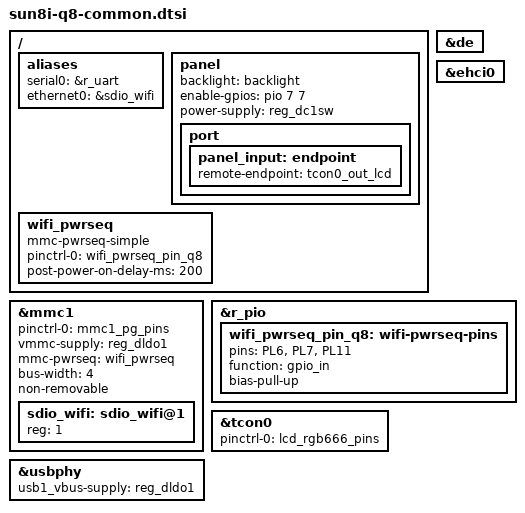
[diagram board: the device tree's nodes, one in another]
#include "sunxi-reference-design-tablet.dtsi"
#include "sun8i-reference-design-tablet.dtsi"
/ {
	aliases {
		serial0 = &r_uart;
		ethernet0 = &sdio_wifi;
	};
	panel: panel {
		backlight = <&backlight>;
		enable-gpios = <&pio 7 7 GPIO_ACTIVE_HIGH>;  
		power-supply = <&reg_dc1sw>;
		port {
			panel_input: endpoint {
				remote-endpoint = <&tcon0_out_lcd>;
			};
		};
	};
	wifi_pwrseq: wifi_pwrseq {
		compatible = "mmc-pwrseq-simple";
		pinctrl-names = "default";
		pinctrl-0 = <&wifi_pwrseq_pin_q8>;
		post-power-on-delay-ms = <200>;
	};
};
&de {
	status = "okay";
};
&ehci0 {
	status  = "okay";
};
&mmc1 {
	pinctrl-names = "default";
	pinctrl-0 = <&mmc1_pg_pins>;
	vmmc-supply = <&reg_dldo1>;
	mmc-pwrseq = <&wifi_pwrseq>;
	bus-width = <4>;
	non-removable;
	status = "okay";
	sdio_wifi: sdio_wifi@1 {
		reg = <1>;
	};
};
&r_pio {
	wifi_pwrseq_pin_q8: wifi-pwrseq-pins {
		pins = "PL6", "PL7", "PL11";
		function = "gpio_in";
		bias-pull-up;
	};
};
&tcon0 {
	pinctrl-names = "default";
	pinctrl-0 = <&lcd_rgb666_pins>;
	status = "okay";
};
&usbphy {
	usb1_vbus-supply = <&reg_dldo1>;
};
